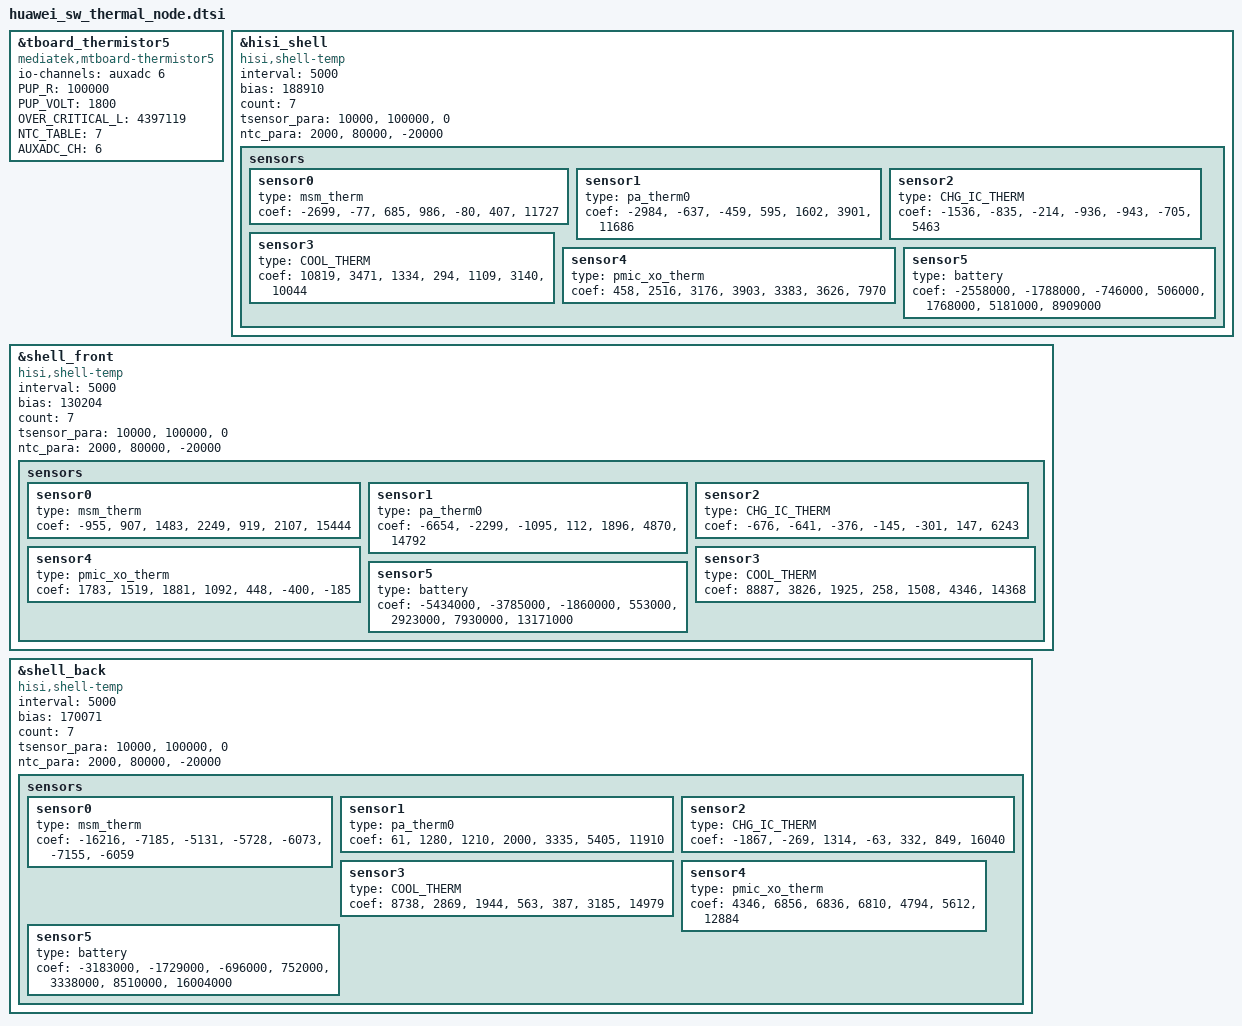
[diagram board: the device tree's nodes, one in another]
&tboard_thermistor5 {
	compatible = "mediatek,mtboard-thermistor5";
	io-channels = <&auxadc 6>;
	io-channel-names = "thermistor-ch4";
	PUP_R = <100000>;
	PUP_VOLT = <1800>;
	OVER_CRITICAL_L = <4397119>;
	NTC_TABLE = <7>;
	AUXADC_CH = <6>;
};

&hisi_shell {
	compatible = "hisi,shell-temp";
	interval = <5000>;
	bias = <188910>;
	count = <7>;
	tsensor_para = "10000","100000","0";
	ntc_para = "2000","80000","-20000";
	status = "ok";
	sensors {
		sensor0 {
			type = "msm_therm";
			coef = "-2699","-77","685","986","-80","407","11727";
		};
		sensor1 {
			type = "pa_therm0";
			coef = "-2984","-637","-459","595","1602","3901","11686";
		};
		sensor2 {
			type = "CHG_IC_THERM";
			coef = "-1536","-835","-214","-936","-943","-705","5463";
		};
		sensor3 {
			type = "COOL_THERM";
			coef = "10819","3471","1334","294","1109","3140","10044";
		};
		sensor4 {
			type = "pmic_xo_therm";
			coef = "458","2516","3176","3903","3383","3626","7970";
		};
		sensor5 {
			type = "battery";
			coef = "-2558000","-1788000","-746000","506000","1768000","5181000","8909000";
		};
	};
};

&shell_front {
	compatible = "hisi,shell-temp";
	interval = <5000>;
	bias = <130204>;
	count = <7>;
	tsensor_para = "10000","100000","0";
	ntc_para = "2000","80000","-20000";
	status = "ok";
	sensors {
		sensor0 {
			type = "msm_therm";
			coef = "-955","907","1483","2249","919","2107","15444";
		};
		sensor1 {
			type = "pa_therm0";
			coef = "-6654","-2299","-1095","112","1896","4870","14792";
		};
		sensor2 {
			type = "CHG_IC_THERM";
			coef = "-676","-641","-376","-145","-301","147","6243";
		};
		sensor3 {
			type = "COOL_THERM";
			coef = "8887","3826","1925","258","1508","4346","14368";
		};
		sensor4 {
			type = "pmic_xo_therm";
			coef = "1783","1519","1881","1092","448","-400","-185";
		};
		sensor5 {
			type = "battery";
			coef = "-5434000","-3785000","-1860000","553000","2923000","7930000","13171000";
		};
	};
};

&shell_back {
	compatible = "hisi,shell-temp";
	interval = <5000>;
	bias = <170071>;
	count = <7>;
	tsensor_para = "10000","100000","0";
	ntc_para = "2000","80000","-20000";
	status = "ok";
	sensors {
		sensor0 {
			type = "msm_therm";
			coef = "-16216","-7185","-5131","-5728","-6073","-7155","-6059";
		};
		sensor1 {
			type = "pa_therm0";
			coef = "61","1280","1210","2000","3335","5405","11910";
		};
		sensor2 {
			type = "CHG_IC_THERM";
			coef = "-1867","-269","1314","-63","332","849","16040";
		};
		sensor3 {
			type = "COOL_THERM";
			coef = "8738","2869","1944","563","387","3185","14979";
		};
		sensor4 {
			type = "pmic_xo_therm";
			coef = "4346","6856","6836","6810","4794","5612","12884";
		};
		sensor5 {
			type = "battery";
			coef = "-3183000","-1729000","-696000","752000","3338000","8510000","16004000";
		};
	};
};

